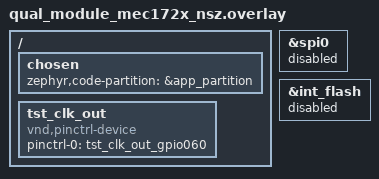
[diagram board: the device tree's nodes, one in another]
/*
 * Copyright (c) 2023 Microchip Technology Inc.
 *
 * SPDX-License-Identifier: Apache-2.0
 */

/ {
    chosen {
        zephyr,code-partition = &app_partition;
    };

    // /delete-node/ flash@c0000;
	// flash0: flash@b0000 {
	// 	reg = <0x000b0000 0x68000>;
	// };

    tst_clk_out: tst_clk_out {
        compatible = "vnd,pinctrl-device";
        pinctrl-0 = < &tst_clk_out_gpio060 >;
        pinctrl-names = "default";
        status = "okay";
    };
};

// &uart1 {
//     status = "okay";
// 	pinctrl-0 = < &uart1_tx_gpio170 &uart1_rx_gpio171 >;
// 	pinctrl-names = "default";
// };

&spi0 {
    status = "disabled";
};

&int_flash {
    status = "disabled";
};
